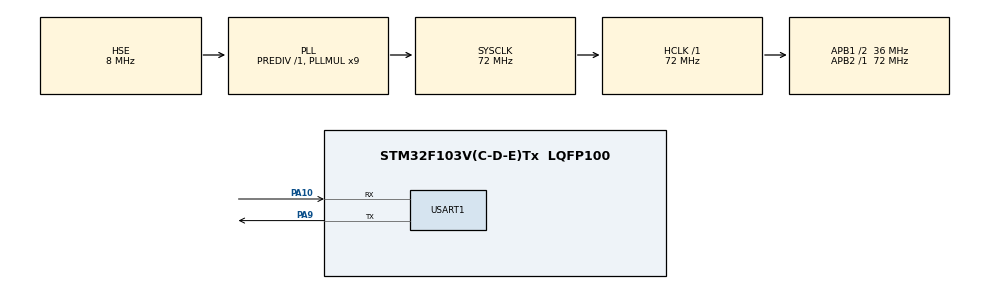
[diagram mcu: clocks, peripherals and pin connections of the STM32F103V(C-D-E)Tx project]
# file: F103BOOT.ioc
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Mcu.Family=STM32F1
Mcu.Name=STM32F103V(C-D-E)Tx
Mcu.Package=LQFP100
NVIC.FLASH_IRQn=true\:0\:0\:false\:false\:true\:true\:true\:true
NVIC.PVD_IRQn=true\:0\:0\:false\:false\:true\:true\:true\:true
NVIC.PriorityGroup=NVIC_PRIORITYGROUP_4
NVIC.RCC_IRQn=true\:0\:0\:false\:false\:true\:true\:false\:true
NVIC.USART1_IRQn=true\:0\:0\:false\:false\:true\:true\:true\:true
OSC_IN.Mode=HSE-External-Oscillator
OSC_IN.Signal=RCC_OSC_IN
OSC_OUT.Mode=HSE-External-Oscillator
OSC_OUT.Signal=RCC_OSC_OUT
PA10.Mode=Asynchronous
PA10.Signal=USART1_RX
PA13.Mode=Serial_Wire
PA13.Signal=SYS_JTMS-SWDIO
PA14.Mode=Serial_Wire
PA14.Signal=SYS_JTCK-SWCLK
PA9.Mode=Asynchronous
PA9.Signal=USART1_TX
ProjectManager.HeapSize=0x800
ProjectManager.StackSize=0x1000
ProjectManager.TargetToolchain=STM32CubeIDE
RCC.AHBFreq_Value=72000000
RCC.APB1CLKDivider=RCC_HCLK_DIV2
RCC.APB1Freq_Value=36000000
RCC.APB1TimFreq_Value=72000000
RCC.APB2Freq_Value=72000000
RCC.APB2TimFreq_Value=72000000
RCC.HCLKFreq_Value=72000000
RCC.PLLMUL=RCC_PLL_MUL9
RCC.PLLSourceVirtual=RCC_PLLSOURCE_HSE
RCC.SYSCLKFreq_VALUE=72000000
RCC.SYSCLKSource=RCC_SYSCLKSOURCE_PLLCLK
RCC.USBFreq_Value=72000000
USART1.VirtualMode=VM_ASYNC
VP_RTC_No_RTC_Output.Mode=RTC_OUT_NO
VP_RTC_VS_RTC_Activate.Mode=RTC_Enabled
VP_RTC_VS_RTC_Calendar.Mode=RTC_Calendar
board=custom

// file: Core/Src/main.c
/* USER CODE BEGIN Header */
/**
  ******************************************************************************
  * @file           : main.c
  * @brief          : Main program body
  ******************************************************************************
  * @attention
  *
  * Copyright (c) 2023 STMicroelectronics.
  * All rights reserved.
  *
  * This software is licensed under terms that can be found in the LICENSE file
  * in the root directory of this software component.
  * If no LICENSE file comes with this software, it is provided AS-IS.
  *
  ******************************************************************************
  */
/* USER CODE END Header */
#include "main.h"
#include "rtc.h"
#include "usart.h"
#include "gpio.h"

/* USER CODE BEGIN Includes */
#include "version.h"
#include <stdio.h>
#include <string.h>
/* USER CODE END Includes */

/* USER CODE BEGIN PTD */
/* Flash layout
 * ------------ 0x08000000
 * |bootloader |
 * |14K        |
 * -------------0x08003800
 * |data       |
 * |2K         |
 * ------------ 0x08004000
 * |image1     |
 * |120K       |
 * -------------0x08022000
 * |image2     |
 * |120K       |
 * -------------0x08040000
 */
/* USER CODE END PTD */

/* USER CODE BEGIN PD */
#define STR(a) #a
#define MAKE_STR(a) STR(a)
#define VERSION "\r\nBootloader ver: " MAKE_STR(SW_VERSION_MAJOR) "." \
	MAKE_STR(SW_VERSION_MINOR) "." MAKE_STR(SW_VERSION_BUILD) "\r\n"

#define APP1_ADDRESS_OFFSET 0x4000
#define APP1_ADDRESS (FLASH_BASE + APP1_ADDRESS_OFFSET)
#define APP2_ADDRESS_OFFSET 0x22000
#define APP2_ADDRESS (FLASH_BASE + APP2_ADDRESS_OFFSET)

#define BOOT_DATA_ADDRESS 0x08003800
/* USER CODE END PD */

/* USER CODE BEGIN PV */
typedef void (*app_func_t)(void);
typedef struct __attribute__((packed))
{
    uint8_t active_image; // Identifies the currently active application image
} config_t;
/* USER CODE END PV */

void SystemClock_Config(void);

/* USER CODE BEGIN 0 */
int _write(int file, char *ptr, int len)
{
    HAL_UART_Transmit(&huart1, (uint8_t*)ptr, len, HAL_MAX_DELAY);
    return len;
}
/* USER CODE END 0 */

int main(void)
{
  /* USER CODE BEGIN 1 */
  app_func_t app;
  uint32_t jump_addr, vt_offset, sp_addr;
  volatile config_t *config = (config_t *)BOOT_DATA_ADDRESS;
  /* USER CODE END 1 */

  /* MCU Configuration--------------------------------------------------------*/

  /* Reset of all peripherals, Initializes the Flash interface and the Systick. */
  HAL_Init();

  /* Configure the system clock */
  SystemClock_Config();

  /* Initialize all configured peripherals */
  MX_GPIO_Init();
  MX_USART1_UART_Init();
  MX_RTC_Init();
  /* USER CODE BEGIN 2 */
  printf(VERSION);

  printf("Start application: ");
  /* Jump to user application */
  if (!config->active_image) {
      printf(" 0\r\n");
      vt_offset = APP1_ADDRESS_OFFSET;
      jump_addr = *(__IO uint32_t *)(APP1_ADDRESS + 4);
      sp_addr = *(__IO uint32_t *)APP1_ADDRESS;
  } else {
      printf(" 1\r\n");
      vt_offset = APP2_ADDRESS_OFFSET;
      jump_addr = *(__IO uint32_t *)(APP2_ADDRESS + 4);
      sp_addr = *(__IO uint32_t *)APP2_ADDRESS;
  }

  // Relocate the vector table
  SCB->VTOR = FLASH_BASE | vt_offset;

  // Set the stack pointer
  __set_MSP(sp_addr);
  // Jump to the application
  app = (app_func_t)jump_addr;
  app();

  return 0;
  /* USER CODE END 2 */

  /* Infinite loop */
  while (1)
  {

  }
}

void SystemClock_Config(void)
{
  RCC_OscInitTypeDef RCC_OscInitStruct = {0};
  RCC_ClkInitTypeDef RCC_ClkInitStruct = {0};
  RCC_PeriphCLKInitTypeDef PeriphClkInit = {0};

  /** Initializes the RCC Oscillators according to the specified parameters
  * in the RCC_OscInitTypeDef structure.
  */
  RCC_OscInitStruct.OscillatorType = RCC_OSCILLATORTYPE_LSI|RCC_OSCILLATORTYPE_HSE;
  RCC_OscInitStruct.HSEState = RCC_HSE_ON;
  RCC_OscInitStruct.HSEPredivValue = RCC_HSE_PREDIV_DIV1;
  RCC_OscInitStruct.HSIState = RCC_HSI_ON;
  RCC_OscInitStruct.LSIState = RCC_LSI_ON;
  RCC_OscInitStruct.PLL.PLLState = RCC_PLL_ON;
  RCC_OscInitStruct.PLL.PLLSource = RCC_PLLSOURCE_HSE;
  RCC_OscInitStruct.PLL.PLLMUL = RCC_PLL_MUL9;
  if (HAL_RCC_OscConfig(&RCC_OscInitStruct) != HAL_OK)
  {
    Error_Handler();
  }

  /** Initializes the CPU, AHB and APB buses clocks
  */
  RCC_ClkInitStruct.ClockType = RCC_CLOCKTYPE_HCLK|RCC_CLOCKTYPE_SYSCLK
                              |RCC_CLOCKTYPE_PCLK1|RCC_CLOCKTYPE_PCLK2;
  RCC_ClkInitStruct.SYSCLKSource = RCC_SYSCLKSOURCE_PLLCLK;
  RCC_ClkInitStruct.AHBCLKDivider = RCC_SYSCLK_DIV1;
  RCC_ClkInitStruct.APB1CLKDivider = RCC_HCLK_DIV2;
  RCC_ClkInitStruct.APB2CLKDivider = RCC_HCLK_DIV1;

  if (HAL_RCC_ClockConfig(&RCC_ClkInitStruct, FLASH_LATENCY_2) != HAL_OK)
  {
    Error_Handler();
  }
  PeriphClkInit.PeriphClockSelection = RCC_PERIPHCLK_RTC;
  PeriphClkInit.RTCClockSelection = RCC_RTCCLKSOURCE_LSI;
  if (HAL_RCCEx_PeriphCLKConfig(&PeriphClkInit) != HAL_OK)
  {
    Error_Handler();
  }
}

void Error_Handler(void)
{
  __disable_irq();
  while (1)
  {
  }
}
